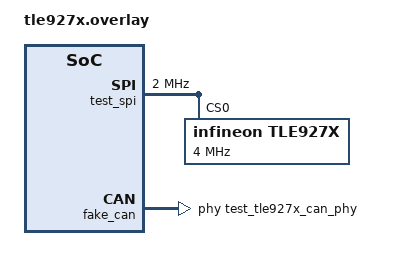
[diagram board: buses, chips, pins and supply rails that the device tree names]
/*
 * SPDX-FileCopyrightText: Copyright (c) 2026 Deere & Company
 * SPDX-FileCopyrightText: Copyright (c) 2026 Linumiz
 *
 * SPDX-License-Identifier: Apache-2.0
 */

/ {
	test {
		#address-cells = <1>;
		#size-cells = <1>;

		test_spi: spi@33334444 {
			#address-cells = <1>;
			#size-cells = <0>;
			compatible = "vnd,spi";
			reg = <0x33334444 0x1000>;
			status = "okay";
			clock-frequency = <2000000>;

			tle927x@0 {
				compatible = "infineon,tle927x";
				reg = <0>;
				spi-max-frequency = <4000000>;
				status = "okay";

				test_tle927x_can_phy: can-transceiver {
					compatible = "infineon,tle927x-can";
					max-bitrate = <5000000>;
					#phy-cells = <0>;
				};
			};
		};
	};
};

&fake_can {
	phys = <&test_tle927x_can_phy>;
};
